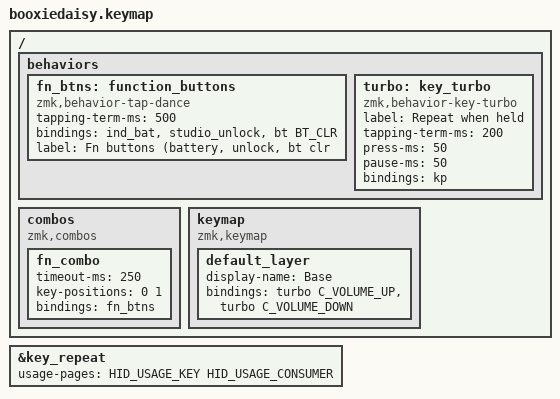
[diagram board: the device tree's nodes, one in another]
#include <behaviors.dtsi>
#include <behaviors/rgbled_widget.dtsi>
#include <dt-bindings/zmk/keys.h>
#include <dt-bindings/zmk/bt.h>
#include <dt-bindings/zmk/ext_power.h>

#define DEF_L 0

&key_repeat {
    usage-pages = <HID_USAGE_KEY HID_USAGE_CONSUMER>;
};

/ {
    behaviors {
        fn_btns: function_buttons {
            compatible = "zmk,behavior-tap-dance";
            #binding-cells = <0>;
            tapping-term-ms = <500>;
            bindings = <&ind_bat>, <&studio_unlock>, <&bt BT_CLR>;
            label = "Fn buttons (battery, unlock, bt clr";
        };
        turbo: key_turbo {
            compatible = "zmk,behavior-key-turbo";
            label = "Repeat when held";
            #binding-cells = <1>;
            tapping-term-ms = <200>;
            press-ms = <50>;
            pause-ms = <50>;
            bindings = <&kp>;
            
        };
    };

    combos {
        compatible = "zmk,combos";
        fn_combo {
            timeout-ms = <250>;
            key-positions = <0 1>;
            bindings = <&fn_btns>;
        };
    };

    keymap {
        compatible = "zmk,keymap";
        default_layer {
            display-name = "Base";
            bindings = <
                &turbo C_VOLUME_UP    &turbo C_VOLUME_DOWN
            >;
        };
    };
};
